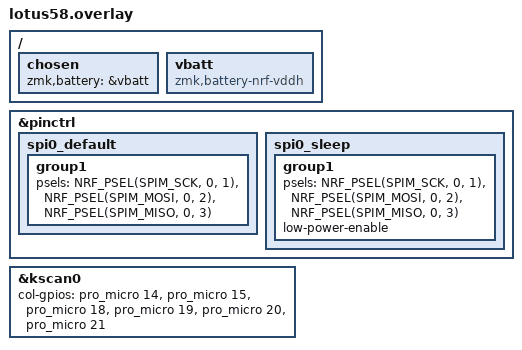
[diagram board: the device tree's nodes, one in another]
&pinctrl {
    /* configuration for spi0 device, default state */
    spi0_default: spi0_default {
        /* node name is arbitrary */
        group1 {
            /* main role: configure P0.01 as SPI clock, P0.02 as SPI MOSI, P0.03 as SPI MISO */
            psels = <NRF_PSEL(SPIM_SCK, 0, 1)>,
                    <NRF_PSEL(SPIM_MOSI, 0, 2)>,
                    <NRF_PSEL(SPIM_MISO, 0, 3)>;
        };
    };

    /* configuration for spi0 device, sleep state */
    spi0_sleep: spi0_sleep {
        group1 {
            /* main role: configure P0.01 as SPI clock, P0.02 as SPI MOSI, P0.03 as SPI MISO */
            psels = <NRF_PSEL(SPIM_SCK, 0, 1)>,
                    <NRF_PSEL(SPIM_MOSI, 0, 2)>,
                    <NRF_PSEL(SPIM_MISO, 0, 3)>;
            low-power-enable;
        };
    };

};

&kscan0 {
    col-gpios
        = <&pro_micro 14  GPIO_ACTIVE_HIGH>
        , <&pro_micro 15  GPIO_ACTIVE_HIGH>
        , <&pro_micro 18  GPIO_ACTIVE_HIGH>
        , <&pro_micro 19  GPIO_ACTIVE_HIGH>
        , <&pro_micro 20  GPIO_ACTIVE_HIGH>
        , <&pro_micro 21  GPIO_ACTIVE_HIGH>
        ;
};
/ {
    chosen {
      zmk,battery = &vbatt;
    };

    vbatt: vbatt {
        compatible = "zmk,battery-nrf-vddh";
    };
};
